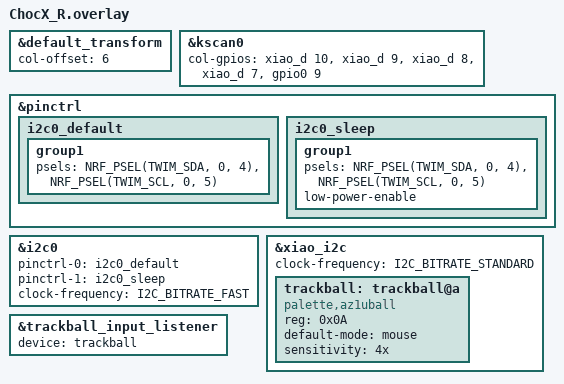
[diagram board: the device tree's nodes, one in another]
// This file was generated from a template. Edit it to match your keyboard.
// See https://zmk.dev/docs/development/hardware-integration/new-shield for more
// instructions.

#include "ChocX.dtsi"

&default_transform {
    col-offset = <6>;
};

&kscan0 {
        col-gpios
            = <&xiao_d 10 GPIO_ACTIVE_HIGH>
            , <&xiao_d 9 GPIO_ACTIVE_HIGH> 
            , <&xiao_d 8 GPIO_ACTIVE_HIGH> 
            , <&xiao_d 7 GPIO_ACTIVE_HIGH> 
            , <&gpio0 9 GPIO_ACTIVE_HIGH>
            ;
};

&pinctrl {
	i2c0_default: i2c0_default {
		group1 {
			psels = <NRF_PSEL(TWIM_SDA, 0, 4)>,
				<NRF_PSEL(TWIM_SCL, 0, 5)>;
		};
	};

	i2c0_sleep: i2c0_sleep {
		group1 {
			psels = <NRF_PSEL(TWIM_SDA, 0, 4)>,
				<NRF_PSEL(TWIM_SCL, 0, 5)>;
		low-power-enable;
		};
	};
};

&i2c0 {
	status = "okay";
	pinctrl-0 = <&i2c0_default>;
	pinctrl-1 = <&i2c0_sleep>;
	pinctrl-names = "default", "sleep";
	clock-frequency = <I2C_BITRATE_FAST>;
};

&xiao_i2c {
    status = "okay";
    clock-frequency = <I2C_BITRATE_STANDARD>;
    trackball: trackball@a {
        compatible = "palette,az1uball";
        reg = <0x0A>;
	default-mode = "mouse";
	sensitivity = "4x";
    };
};

&trackball_input_listener {
    status = "okay";
    device = <&trackball>;
};
